VERSION ""

NS_ :

BS_:

BU_: XXX

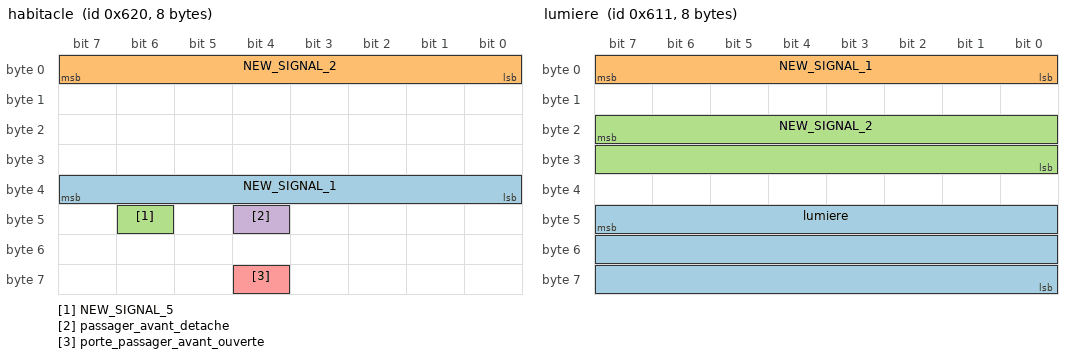
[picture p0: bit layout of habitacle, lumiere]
BO_ 1568 habitacle: 8 XXX
 SG_ NEW_SIGNAL_1 : 39|8@0+ (1,0) [0|65535] "" XXX
 SG_ NEW_SIGNAL_2 : 0|8@1+ (1,0) [0|255] "" XXX
 SG_ NEW_SIGNAL_5 : 46|1@0+ (1,0) [0|1023] "" XXX
 SG_ passager_avant_detache : 44|1@0+ (1,0) [0|255] "" XXX
 SG_ porte_passager_avant_ouverte : 60|1@0+ (1,0) [0|3] "" XXX

BO_ 608 rotation_volant: 8 XXX
 SG_ rotation_volant : 47|24@0- (1,0) [0|16777215] "" XXX

BO_ 705 accelerateur: 8 XXX
 SG_ accelerateur : 55|16@0+ (1,0) [0|255] "" XXX
 SG_ NEW_SIGNAL_1 : 15|32@0+ (1,0) [0|4294967295] "" XXX

BO_ 708 RPM: 8 XXX
 SG_ RPM : 7|16@0+ (1,0) [0|65535] "" XXX
 SG_ vibration_du_bloc : 55|16@0+ (1,0) [0|65535] "" XXX

BO_ 178 vitesse: 8 XXX
 SG_ vitesse : 7|48@0+ (1,0) [0|281474976710655] "" XXX

BO_ 176 NEW_MSG_2: 8 XXX
 SG_ NEW_SIGNAL_1 : 7|48@0+ (1,0) [0|281474976710655] "" XXX

BO_ 180 embrayage: 8 XXX
 SG_ pedale_d_embrayage : 39|32@0- (1,0) [0|4294967295] "" XXX

BO_ 947 NEW_MSG_4: 8 XXX
 SG_ NEW_SIGNAL_1 : 7|24@0+ (1,0) [0|16777215] "" XXX

BO_ 920 NEW_MSG_5: 8 XXX
 SG_ NEW_SIGNAL_1 : 7|16@0+ (1,0) [0|65535] "" XXX

BO_ 1552 NEW_MSG_6: 8 XXX
 SG_ NEW_SIGNAL_1 : 23|24@0+ (1,0) [0|16777215] "" XXX

BO_ 1553 lumiere: 8 XXX
 SG_ lumiere : 47|24@0+ (1,0) [0|16777215] "" XXX
 SG_ NEW_SIGNAL_1 : 0|8@1+ (1,0) [0|255] "" XXX
 SG_ NEW_SIGNAL_2 : 23|16@0+ (1,0) [0|65535] "" XXX

BO_ 896 NEW_MSG_1: 8 XXX
 SG_ NEW_SIGNAL_1 : 48|8@1+ (1,0) [0|255] "" XXX
 SG_ NEW_SIGNAL_2 : 8|8@1+ (1,0) [0|255] "" XXX

BO_ 928 NEW_MSG_7: 8 XXX
 SG_ NEW_SIGNAL_1 : 56|8@1+ (1,0) [0|255] "" XXX

BO_ 1088 NEW_MSG_8: 8 XXX
 SG_ NEW_SIGNAL_1 : 7|16@0+ (1,0) [0|65535] "" XXX

BO_ 1090 NEW_MSG_9: 8 XXX
 SG_ NEW_SIGNAL_1 : 7|16@0+ (1,0) [0|65535] "" XXX

BO_ 1217 NEW_MSG_10: 8 XXX
 SG_ NEW_SIGNAL_1 : 23|16@0+ (1,0) [0|65535] "" XXX
 SG_ NEW_SIGNAL_2 : 0|8@1+ (1,0) [0|255] "" XXX

BO_ 1219 NEW_MSG_11: 8 XXX
 SG_ NEW_SIGNAL_1 : 23|16@0+ (1,0) [0|65535] "" XXX
 SG_ NEW_SIGNAL_2 : 0|8@1+ (1,0) [0|255] "" XXX

BO_ 1224 NEW_MSG_12: 8 XXX
 SG_ NEW_SIGNAL_1 : 23|16@0+ (1,0) [0|4294967295] "" XXX
 SG_ NEW_SIGNAL_2 : 0|8@1+ (1,0) [0|255] "" XXX

BO_ 906 NEW_MSG_13: 8 XXX
 SG_ NEW_SIGNAL_1 : 7|16@0+ (1,0) [0|65535] "" XXX

BO_ 944 NEW_MSG_14: 8 XXX
 SG_ NEW_SIGNAL_1 : 24|8@1+ (1,0) [0|255] "" XXX

BO_ 945 NEW_MSG_15: 8 XXX
 SG_ NEW_SIGNAL_1 : 23|16@0+ (1,0) [0|65535] "" XXX

BO_ 948 NEW_MSG_16: 8 XXX
 SG_ NEW_SIGNAL_1 : 23|16@0+ (1,0) [0|65535] "" XXX

BO_ 1244 NEW_MSG_17: 8 XXX
 SG_ NEW_SIGNAL_1 : 24|8@1+ (1,0) [0|255] "" XXX
 SG_ NEW_SIGNAL_2 : 0|8@1+ (1,0) [0|255] "" XXX

BO_ 1245 NEW_MSG_18: 8 XXX
 SG_ NEW_SIGNAL_1 : 24|8@1+ (1,0) [0|255] "" XXX
 SG_ NEW_SIGNAL_2 : 0|8@1+ (1,0) [0|255] "" XXX

BO_ 1569 NEW_MSG_19: 8 XXX
 SG_ NEW_SIGNAL_1 : 0|8@1+ (1,0) [0|255] "" XXX

BO_ 1570 NEW_MSG_20: 8 XXX
 SG_ NEW_SIGNAL_1 : 0|8@1+ (1,0) [0|255] "" XXX

BO_ 1584 NEW_MSG_21: 8 XXX
 SG_ NEW_SIGNAL_1 : 0|3@1+ (1,0) [0|255] "" XXX
 SG_ NEW_SIGNAL_2 : 4|1@0+ (1,0) [0|3] "" XXX

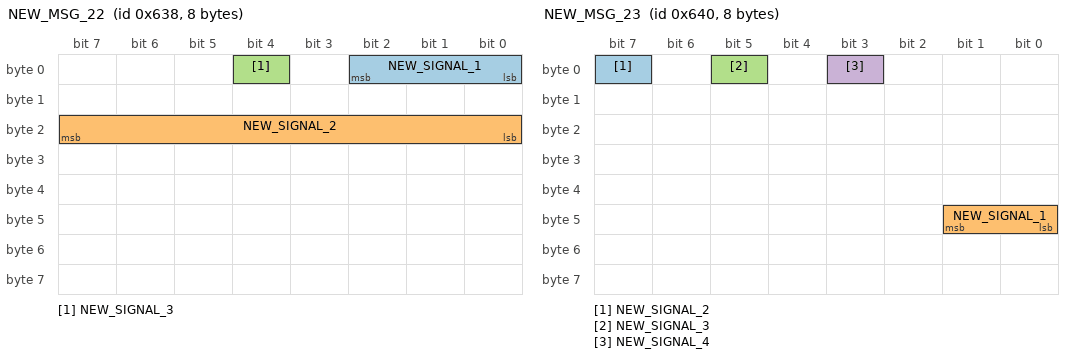
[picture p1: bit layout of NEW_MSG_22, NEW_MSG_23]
BO_ 1592 NEW_MSG_22: 8 XXX
 SG_ NEW_SIGNAL_1 : 0|3@1+ (1,0) [0|255] "" XXX
 SG_ NEW_SIGNAL_2 : 16|8@1+ (1,0) [0|255] "" XXX
 SG_ NEW_SIGNAL_3 : 4|1@0+ (1,0) [0|3] "" XXX

BO_ 1600 NEW_MSG_23: 8 XXX
 SG_ NEW_SIGNAL_2 : 7|1@0+ (1,0) [0|3] "" XXX
 SG_ NEW_SIGNAL_1 : 40|2@1+ (1,0) [0|3] "" XXX
 SG_ NEW_SIGNAL_3 : 5|1@0+ (1,0) [0|3] "" XXX
 SG_ NEW_SIGNAL_4 : 3|1@1+ (1,0) [0|3] "" XXX

BO_ 2015 NEW_MSG_24: 8 XXX
 SG_ NEW_SIGNAL_1 : 7|24@0+ (1,0) [0|16777215] "" XXX

BO_ 417018865 NEW_MSG_25: 8 XXX
 SG_ NEW_SIGNAL_1 : 7|24@0+ (1,0) [0|16777215] "" XXX

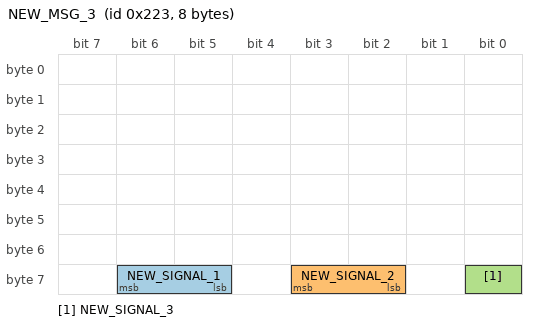
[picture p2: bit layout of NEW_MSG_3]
BO_ 547 NEW_MSG_3: 8 XXX
 SG_ NEW_SIGNAL_1 : 62|2@0+ (1,0) [0|3] "" XXX
 SG_ NEW_SIGNAL_2 : 58|2@1+ (1,0) [0|3] "" XXX
 SG_ NEW_SIGNAL_3 : 56|1@1+ (1,0) [0|3] "" XXX

BO_ 548 brake_light: 8 XXX
 SG_ brake_light : 5|1@0+ (1,0) [0|3] "" XXX
